# HR_C7000_DM32 register map
Vendor: Dahua Technology (chip); Baofeng (radio product); Series: HR_C7000; File version: 0.1-dm32re-draft
CPU: other r0p0, little endian, no MPU, no FPU, 0 interrupt priority bits
Registers are 32-bit, read-write, reset 0x0 unless marked. A register's access mark holds for its fields unless they carry their own. Offsets are from the block's base; [hi:lo] are bit positions; {n}, {i} and the like mark numbered series; <NAME> marks a mode.

## PIC (part 1 of 2) — Programmable interrupt controller, 64 sources of which Table 30 assigns 38 (DS §4.7, p.166-187; Register Table 5 p.170-172). This is the chip's real interrupt controller, not the CK803S built-in VIC at 0xE000E100: the stock firmware makes no 0xE000xxxx accesses (program-flash sweep and live register reads). SOURCE vs VECTOR: source n is bit n of PIC_MODE/PO/MASK/INT_ST/FFLAG_L (n < 32) or bit n-32 of PIC_MODE_1/PO_1/MASK_1/INT_ST_1/FFLAG_H, and byte n%4 of PIC_PRIOR<4*(n/4)>; the CPU sees it as vector n + PIC_VECTOR.vector0 = n + 32 at reset. Table 30 (p.168-169), source/vector: 0 reserved/32, 1 TIMER_1/33, 2 TIMER_2/34, 3 TIMER_3/35, 4 TIMER_4/36, 5 TIMER_5/37, 6 TIMER_6/38, 7 I2C1/39, 8 I2C0/40, 9 I2C2/41, 10 UART1/42, 11 UART2/43, 12 UART0/44, 13 UART3/45, 14 GPIOB/46, 15 GPIOA/47, 16 SPI0/48, 17 GPIOC/49, 18 PWM/50, 19 RTC/51, 20 SDIO/52, 21 USB/53, 22 SPI1/54, 23 SPI2/55, 24 LCSFC/56, 25 DAC/57, 26 ADC/58, 27 PCM_rd_data_interp/59, 28 PCM_wr_data_interp/60, 29 System_inter/61, 30 Time_slot_inter_tx/62, 31 Time_slot_inter_rx/63, 32 Rf_tx_inter/64, 33 Rf_rx_inter/65, 34 SlaveSPI0/66, 35 SlaveSPI1/67, 36 SlaveSPI2/68, 37 Codec_interp/69; all level-triggered, active high. CORRECTED 2026-10-10: the hand-maintained description this replaced listed CPU vectors as 'source assignments' (TIMER_1=33, TIMER_2-4=34-36, UART3=45, GPIOC=49, PCM_rd/wr_data_interp=59/60, System_inter=61, Time_slot_inter_rx=63, Rf_rx_inter=65, Codec_interp=69, and UART1/2/0=42/43/44, ADC=58, Rf_tx=64). Those are vectors; the sources are 1, 2-4, 13, 17, 27/28, 29, 31, 33, 37, 10/11/12, 26, 32. DRV's VECTOR_* defines (C7000_DRV.h: VECTOR_TIMER1-4=33-36, UART3=45, GPIOC=49, PCM_rd/wr_data_interp=59/60, System_inter=61, Time_slot_inter_rx=63, Rf_rx_inter=65, Codec_interp=69; bsp_vic.h: VECTOR_TIMER0=33, VECTOR_USB=53) are vectors too, passed to CKSetIsrVector, which unmasks bit (vector - 32); they agree with Table 30's vector column at every entry. The earlier note that a live trace's 'Time_slot_inter_tx = source 30' and DRV's 'Time_slot_inter_rx = 63' were an unverified TX/RX pair is resolved: Table 30 has tx at source 30/vector 62 and rx at source 31/vector 63. RTOS TICK: TIMER_1 (timer channel 0) is PIC source 1, CPU vector 33. Confirmed on hardware 2026-10-01 (OpenRTX bring-up on a DM-32UV, boot console log): with source 33 unmasked instead, the timer expired and held its line but nothing was delivered; with source 1 unmasked the ISR fired. The stock firmware registers its tick ISR with vector 33, stored at ISR-table index 33 - 32 = 1 (flash 0x0306cf70/0x0306cf38; dm32uv-qemu board-model notes (DM32-BOARD-MODEL.md), session 7). Register names and offsets also come from DRV bsp_vic.h ('Interrupt Controller definitions', Wang Huibin, 2013-05-13; in the DemoUV008 source tree at ucos3/include/bsp/bsp_vic.h), which agrees with Register Table 5 at every offset. Its CKIntcInit (bsp_vic.c) writes MODE = 0, PO = 0xffffffff, MASK = 0xffffffff, MODE_1 = 0, PO_1 = 0xffffffff, then MASK a second time where MASK_1 was probably meant, then INT_ST/INT_ST_1 = 0xffffffff. FW: 24 access sites in 2 code regions, all to MODE/PO/MASK/INT_ST and their upper-bank siblings; no access to PIC_VECTOR, PIC_COW1/2, PIC_PRIOR*, PIC_SYNC or PIC_FFLAG_* was found by the program-flash sweep, which does not cover IRAM (where the interrupt entry path runs).
Base 0x17000000
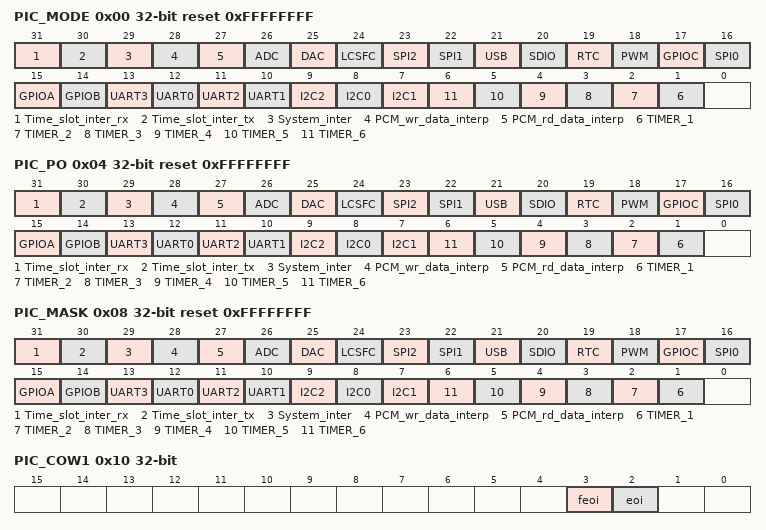
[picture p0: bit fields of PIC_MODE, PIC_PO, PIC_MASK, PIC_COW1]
0x00 PIC_MODE reset 0xFFFFFFFF — Trigger mode select, sources 0-31. DS §4.7.6.1 p.172. FW: 0 reads, 2 writes. Bit n is source 0+n (sources 0-31). The datasheet prints one [31:0] field; it is split here into one bit per source named in Table 30 (p.168-169); bits with no assigned source have no field. Reset is all edge-triggered, while Table 30 requires level/high: DRV's CKIntcInit (bsp_vic.c) writes PIC_MODE = 0 and PIC_PO = 0xffffffff. FW writes this register (count above). Offset previously confirmed by DRV bsp_vic.h. Reset 0xffffffff (DS).
  [31] Time_slot_inter_rx — Trigger mode of source 31 (Time_slot_inter_rx, vector 63). 1: edge; 0: level. Table 30 specifies level-triggered, active high [reset 0x1] [access RW]
  [30] Time_slot_inter_tx — Trigger mode of source 30 (Time_slot_inter_tx, vector 62). 1: edge; 0: level. Table 30 specifies level-triggered, active high [reset 0x1] [access RW]
  [29] System_inter — Trigger mode of source 29 (System_inter, vector 61). 1: edge; 0: level. Table 30 specifies level-triggered, active high [reset 0x1] [access RW]
  [28] PCM_wr_data_interp — Trigger mode of source 28 (PCM_wr_data_interp, vector 60). 1: edge; 0: level. Table 30 specifies level-triggered, active high [reset 0x1] [access RW]
  [27] PCM_rd_data_interp — Trigger mode of source 27 (PCM_rd_data_interp, vector 59). 1: edge; 0: level. Table 30 specifies level-triggered, active high [reset 0x1] [access RW]
  [26] ADC — Trigger mode of source 26 (ADC, vector 58). 1: edge; 0: level. Table 30 specifies level-triggered, active high [reset 0x1] [access RW]
  [25] DAC — Trigger mode of source 25 (DAC, vector 57). 1: edge; 0: level. Table 30 specifies level-triggered, active high [reset 0x1] [access RW]
  [24] LCSFC — Trigger mode of source 24 (LCSFC, vector 56). 1: edge; 0: level. Table 30 specifies level-triggered, active high [reset 0x1] [access RW]
  [23] SPI2 — Trigger mode of source 23 (SPI2, vector 55). 1: edge; 0: level. Table 30 specifies level-triggered, active high [reset 0x1] [access RW]
  [22] SPI1 — Trigger mode of source 22 (SPI1, vector 54). 1: edge; 0: level. Table 30 specifies level-triggered, active high [reset 0x1] [access RW]
  [21] USB — Trigger mode of source 21 (USB, vector 53). 1: edge; 0: level. Table 30 specifies level-triggered, active high [reset 0x1] [access RW]
  [20] SDIO — Trigger mode of source 20 (SDIO, vector 52). 1: edge; 0: level. Table 30 specifies level-triggered, active high [reset 0x1] [access RW]
  [19] RTC — Trigger mode of source 19 (RTC, vector 51). 1: edge; 0: level. Table 30 specifies level-triggered, active high [reset 0x1] [access RW]
  [18] PWM — Trigger mode of source 18 (PWM, vector 50). 1: edge; 0: level. Table 30 specifies level-triggered, active high [reset 0x1] [access RW]
  [17] GPIOC — Trigger mode of source 17 (GPIOC, vector 49). 1: edge; 0: level. Table 30 specifies level-triggered, active high [reset 0x1] [access RW]
  [16] SPI0 — Trigger mode of source 16 (SPI0, vector 48). 1: edge; 0: level. Table 30 specifies level-triggered, active high [reset 0x1] [access RW]
  [15] GPIOA — Trigger mode of source 15 (GPIOA, vector 47). 1: edge; 0: level. Table 30 specifies level-triggered, active high [reset 0x1] [access RW]
  [14] GPIOB — Trigger mode of source 14 (GPIOB, vector 46). 1: edge; 0: level. Table 30 specifies level-triggered, active high [reset 0x1] [access RW]
  [13] UART3 — Trigger mode of source 13 (UART3, vector 45). 1: edge; 0: level. Table 30 specifies level-triggered, active high [reset 0x1] [access RW]
  [12] UART0 — Trigger mode of source 12 (UART0, vector 44). 1: edge; 0: level. Table 30 specifies level-triggered, active high [reset 0x1] [access RW]
  [11] UART2 — Trigger mode of source 11 (UART2, vector 43). 1: edge; 0: level. Table 30 specifies level-triggered, active high [reset 0x1] [access RW]
  [10] UART1 — Trigger mode of source 10 (UART1, vector 42). 1: edge; 0: level. Table 30 specifies level-triggered, active high [reset 0x1] [access RW]
  [9] I2C2 — Trigger mode of source 9 (I2C2, vector 41). 1: edge; 0: level. Table 30 specifies level-triggered, active high [reset 0x1] [access RW]
  [8] I2C0 — Trigger mode of source 8 (I2C0, vector 40). 1: edge; 0: level. Table 30 specifies level-triggered, active high [reset 0x1] [access RW]
  [7] I2C1 — Trigger mode of source 7 (I2C1, vector 39). 1: edge; 0: level. Table 30 specifies level-triggered, active high [reset 0x1] [access RW]
  [n] TIMER_{n} (n=1..6) — Trigger mode of source {n} (TIMER_{n}, vector {n+32}). 1: edge; 0: level. Table 30 specifies level-triggered, active high [reset 0x1] [access RW]
0x04 PIC_PO reset 0xFFFFFFFF — Trigger polarity select, sources 0-31. DS §4.7.6.2 p.172. FW: 0 reads, 2 writes. Bit n is source 0+n (sources 0-31). The datasheet prints one [31:0] field; it is split here into one bit per source named in Table 30 (p.168-169); bits with no assigned source have no field. Offset also in DRV bsp_vic.h. Reset 0xffffffff (DS).
  [31] Time_slot_inter_rx — Trigger polarity of source 31 (Time_slot_inter_rx, vector 63). 1: rising edge / high level; 0: falling edge / low level [reset 0x1] [access RW]
  [30] Time_slot_inter_tx — Trigger polarity of source 30 (Time_slot_inter_tx, vector 62). 1: rising edge / high level; 0: falling edge / low level [reset 0x1] [access RW]
  [29] System_inter — Trigger polarity of source 29 (System_inter, vector 61). 1: rising edge / high level; 0: falling edge / low level [reset 0x1] [access RW]
  [28] PCM_wr_data_interp — Trigger polarity of source 28 (PCM_wr_data_interp, vector 60). 1: rising edge / high level; 0: falling edge / low level [reset 0x1] [access RW]
  [27] PCM_rd_data_interp — Trigger polarity of source 27 (PCM_rd_data_interp, vector 59). 1: rising edge / high level; 0: falling edge / low level [reset 0x1] [access RW]
  [26] ADC — Trigger polarity of source 26 (ADC, vector 58). 1: rising edge / high level; 0: falling edge / low level [reset 0x1] [access RW]
  [25] DAC — Trigger polarity of source 25 (DAC, vector 57). 1: rising edge / high level; 0: falling edge / low level [reset 0x1] [access RW]
  [24] LCSFC — Trigger polarity of source 24 (LCSFC, vector 56). 1: rising edge / high level; 0: falling edge / low level [reset 0x1] [access RW]
  [23] SPI2 — Trigger polarity of source 23 (SPI2, vector 55). 1: rising edge / high level; 0: falling edge / low level [reset 0x1] [access RW]
  [22] SPI1 — Trigger polarity of source 22 (SPI1, vector 54). 1: rising edge / high level; 0: falling edge / low level [reset 0x1] [access RW]
  [21] USB — Trigger polarity of source 21 (USB, vector 53). 1: rising edge / high level; 0: falling edge / low level [reset 0x1] [access RW]
  [20] SDIO — Trigger polarity of source 20 (SDIO, vector 52). 1: rising edge / high level; 0: falling edge / low level [reset 0x1] [access RW]
  [19] RTC — Trigger polarity of source 19 (RTC, vector 51). 1: rising edge / high level; 0: falling edge / low level [reset 0x1] [access RW]
  [18] PWM — Trigger polarity of source 18 (PWM, vector 50). 1: rising edge / high level; 0: falling edge / low level [reset 0x1] [access RW]
  [17] GPIOC — Trigger polarity of source 17 (GPIOC, vector 49). 1: rising edge / high level; 0: falling edge / low level [reset 0x1] [access RW]
  [16] SPI0 — Trigger polarity of source 16 (SPI0, vector 48). 1: rising edge / high level; 0: falling edge / low level [reset 0x1] [access RW]
  [15] GPIOA — Trigger polarity of source 15 (GPIOA, vector 47). 1: rising edge / high level; 0: falling edge / low level [reset 0x1] [access RW]
  [14] GPIOB — Trigger polarity of source 14 (GPIOB, vector 46). 1: rising edge / high level; 0: falling edge / low level [reset 0x1] [access RW]
  [13] UART3 — Trigger polarity of source 13 (UART3, vector 45). 1: rising edge / high level; 0: falling edge / low level [reset 0x1] [access RW]
  [12] UART0 — Trigger polarity of source 12 (UART0, vector 44). 1: rising edge / high level; 0: falling edge / low level [reset 0x1] [access RW]
  [11] UART2 — Trigger polarity of source 11 (UART2, vector 43). 1: rising edge / high level; 0: falling edge / low level [reset 0x1] [access RW]
  [10] UART1 — Trigger polarity of source 10 (UART1, vector 42). 1: rising edge / high level; 0: falling edge / low level [reset 0x1] [access RW]
  [9] I2C2 — Trigger polarity of source 9 (I2C2, vector 41). 1: rising edge / high level; 0: falling edge / low level [reset 0x1] [access RW]
  [8] I2C0 — Trigger polarity of source 8 (I2C0, vector 40). 1: rising edge / high level; 0: falling edge / low level [reset 0x1] [access RW]
  [7] I2C1 — Trigger polarity of source 7 (I2C1, vector 39). 1: rising edge / high level; 0: falling edge / low level [reset 0x1] [access RW]
  [n] TIMER_{n} (n=1..6) — Trigger polarity of source {n} (TIMER_{n}, vector {n+32}). 1: rising edge / high level; 0: falling edge / low level [reset 0x1] [access RW]
0x08 PIC_MASK reset 0xFFFFFFFF — Interrupt mask, sources 0-31. DS §4.7.6.3 p.173. FW: 2 reads, 4 writes. Bit n is source 0+n (sources 0-31). The datasheet prints one [31:0] field; it is split here into one bit per source named in Table 30 (p.168-169); bits with no assigned source have no field. All sources are masked at reset. FW: irq_controller_unmask_and_register_handler @0x0306cf70 and sram_state_word_bit_clear @0x03001c50 take a CPU VECTOR v >= 0x20 and clear bit (v - 0x20) here when v < 0x40, else bit (v - 0x40) of PIC_MASK_1; DRV bsp_vic.c CK_VIC_EnNormalIrq does the same (bit irq_num - 32). So bit n here is source n, as the datasheet says. CORRECTED 2026-10-10: the hand-maintained entry this replaced said PIC_MASK covers sources 32-63 and PIC_MASK_1 sources 64+, reading the firmware's vector argument as a source number. Reset 0xffffffff (DS).
  [31] Time_slot_inter_rx — Mask for source 31 (Time_slot_inter_rx, vector 63). 1: masked; 0: request detection enabled [reset 0x1] [access RW]
  [30] Time_slot_inter_tx — Mask for source 30 (Time_slot_inter_tx, vector 62). 1: masked; 0: request detection enabled [reset 0x1] [access RW]
  [29] System_inter — Mask for source 29 (System_inter, vector 61). 1: masked; 0: request detection enabled [reset 0x1] [access RW]
  [28] PCM_wr_data_interp — Mask for source 28 (PCM_wr_data_interp, vector 60). 1: masked; 0: request detection enabled [reset 0x1] [access RW]
  [27] PCM_rd_data_interp — Mask for source 27 (PCM_rd_data_interp, vector 59). 1: masked; 0: request detection enabled [reset 0x1] [access RW]
  [26] ADC — Mask for source 26 (ADC, vector 58). 1: masked; 0: request detection enabled [reset 0x1] [access RW]
  [25] DAC — Mask for source 25 (DAC, vector 57). 1: masked; 0: request detection enabled [reset 0x1] [access RW]
  [24] LCSFC — Mask for source 24 (LCSFC, vector 56). 1: masked; 0: request detection enabled [reset 0x1] [access RW]
  [23] SPI2 — Mask for source 23 (SPI2, vector 55). 1: masked; 0: request detection enabled [reset 0x1] [access RW]
  [22] SPI1 — Mask for source 22 (SPI1, vector 54). 1: masked; 0: request detection enabled [reset 0x1] [access RW]
  [21] USB — Mask for source 21 (USB, vector 53). 1: masked; 0: request detection enabled [reset 0x1] [access RW]
  [20] SDIO — Mask for source 20 (SDIO, vector 52). 1: masked; 0: request detection enabled [reset 0x1] [access RW]
  [19] RTC — Mask for source 19 (RTC, vector 51). 1: masked; 0: request detection enabled [reset 0x1] [access RW]
  [18] PWM — Mask for source 18 (PWM, vector 50). 1: masked; 0: request detection enabled [reset 0x1] [access RW]
  [17] GPIOC — Mask for source 17 (GPIOC, vector 49). 1: masked; 0: request detection enabled [reset 0x1] [access RW]
  [16] SPI0 — Mask for source 16 (SPI0, vector 48). 1: masked; 0: request detection enabled [reset 0x1] [access RW]
  [15] GPIOA — Mask for source 15 (GPIOA, vector 47). 1: masked; 0: request detection enabled [reset 0x1] [access RW]
  [14] GPIOB — Mask for source 14 (GPIOB, vector 46). 1: masked; 0: request detection enabled [reset 0x1] [access RW]
  [13] UART3 — Mask for source 13 (UART3, vector 45). 1: masked; 0: request detection enabled [reset 0x1] [access RW]
  [12] UART0 — Mask for source 12 (UART0, vector 44). 1: masked; 0: request detection enabled [reset 0x1] [access RW]
  [11] UART2 — Mask for source 11 (UART2, vector 43). 1: masked; 0: request detection enabled [reset 0x1] [access RW]
  [10] UART1 — Mask for source 10 (UART1, vector 42). 1: masked; 0: request detection enabled [reset 0x1] [access RW]
  [9] I2C2 — Mask for source 9 (I2C2, vector 41). 1: masked; 0: request detection enabled [reset 0x1] [access RW]
  [8] I2C0 — Mask for source 8 (I2C0, vector 40). 1: masked; 0: request detection enabled [reset 0x1] [access RW]
  [7] I2C1 — Mask for source 7 (I2C1, vector 39). 1: masked; 0: request detection enabled [reset 0x1] [access RW]
  [n] TIMER_{n} (n=1..6) — Mask for source {n} (TIMER_{n}, vector {n+32}). 1: masked; 0: request detection enabled [reset 0x1] [access RW]
0x0C PIC_VECTOR reset 0x20 — Interrupt vector base address. DS §4.7.6.4 p.174. Source x is delivered to the CPU as vector x + vector0; with the reset vector0 = 32 this gives Table 30's 'default interrupt vector' column (source + 32). The stock firmware's dispatcher indexes its ISR table by (vector - 32) (IRAM 0x1064a; dm32uv-qemu board-model notes (DM32-BOARD-MODEL.md), session 7). Offset first identified from a live register read of a running radio, and also in DRV bsp_vic.h. Reset 0x20 (DS).
  [6:0] vector0 — Vector number for IRQ0, range 32-112. Source x is delivered as vector x + vector0 [reset 0x20] [access RW]
0x10 PIC_COW1 wo — End of interruption. DS §4.7.6.5 p.174. The hand-maintained entry this replaced guessed a 'clear-on-write ack'; the datasheet defines it as the end-of-interrupt register (eoi for normal, feoi for fast interrupts). Offset also in DRV bsp_vic.h. FW: no write found by the program-flash sweep, which does not cover the IRAM interrupt entry path. Reset 0x0 (DS).
  [3] feoi — When the CPU finishes processing the fast interrupt, it writes 1 to this bit . After obtaining FEOI , the interrupt controller clears the FISR register and pulls the FINT (active low) request line high. 1 ： CPU interrupt service ends; 0 ： CPU Still processing outage service. [reset 0x0] [access WO]
  [2] eoi — When the CPU finishes processing the interrupt, it writes 1 to this bit . After receiving the eoi signal, the interrupt controller will clear the ISR register and pull the INT (active low) request line high. 1 ： CPU interrupt service ends; 0 ： CPU Still processing outage service. [reset 0x0] [access WO]
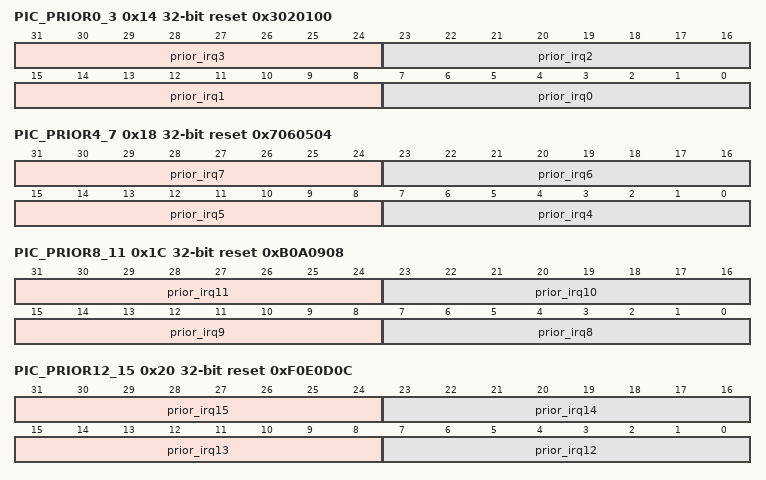
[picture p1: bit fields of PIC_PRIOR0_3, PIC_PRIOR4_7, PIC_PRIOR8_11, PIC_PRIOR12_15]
0x14 PIC_PRIOR0_3 reset 0x3020100 — Priority counter initial values, sources 0-3. DS §4.7.6.6 p.174. Sources 0-3 are unassigned, TIMER_1, TIMER_2, TIMER_3; one byte each, source 0 in [7:0]. Offset also in DRV bsp_vic.h as PIC_PRIOR0_3. FW: no access found by the program-flash sweep (which does not cover IRAM code). Reset 0x3020100 (DS).
  [31:24] prior_irq3 — Priority counter initial value for source 3 (TIMER_3, vector 35); smaller is higher priority. Used only when PIC_COW2.priority = 1. Reset value n gives the same order as the fixed default IRQ0 > IRQ1 > ... > IRQ63 [reset 0x3] [access RW]
  [23:16] prior_irq2 — Priority counter initial value for source 2 (TIMER_2, vector 34); smaller is higher priority. Used only when PIC_COW2.priority = 1. Reset value n gives the same order as the fixed default IRQ0 > IRQ1 > ... > IRQ63 [reset 0x2] [access RW]
  [15:8] prior_irq1 — Priority counter initial value for source 1 (TIMER_1, vector 33); smaller is higher priority. Used only when PIC_COW2.priority = 1. Reset value n gives the same order as the fixed default IRQ0 > IRQ1 > ... > IRQ63 [reset 0x1] [access RW]
  [7:0] prior_irq0 — Priority counter initial value for source 0 (printed 'reserve' in Table 30); smaller is higher priority. Used only when PIC_COW2.priority = 1. Reset value n gives the same order as the fixed default IRQ0 > IRQ1 > ... > IRQ63 [reset 0x0] [access RW]
0x18 PIC_PRIOR4_7 reset 0x7060504 — Priority counter initial values, sources 4-7. DS §4.7.6.7 p.176. Sources 4-7 are TIMER_4, TIMER_5, TIMER_6, I2C1; one byte each, source 4 in [7:0]. Offset also in DRV bsp_vic.h as PIC_PRIOR4_7. FW: no access found by the program-flash sweep (which does not cover IRAM code). Reset 0x7060504 (DS).
  [31:24] prior_irq7 — Priority counter initial value for source 7 (I2C1, vector 39); smaller is higher priority. Used only when PIC_COW2.priority = 1. Reset value n gives the same order as the fixed default IRQ0 > IRQ1 > ... > IRQ63 [reset 0x7] [access RW]
  [23:16] prior_irq6 — Priority counter initial value for source 6 (TIMER_6, vector 38); smaller is higher priority. Used only when PIC_COW2.priority = 1. Reset value n gives the same order as the fixed default IRQ0 > IRQ1 > ... > IRQ63 [reset 0x6] [access RW]
  [15:8] prior_irq5 — Priority counter initial value for source 5 (TIMER_5, vector 37); smaller is higher priority. Used only when PIC_COW2.priority = 1. Reset value n gives the same order as the fixed default IRQ0 > IRQ1 > ... > IRQ63 [reset 0x5] [access RW]
  [7:0] prior_irq4 — Priority counter initial value for source 4 (TIMER_4, vector 36); smaller is higher priority. Used only when PIC_COW2.priority = 1. Reset value n gives the same order as the fixed default IRQ0 > IRQ1 > ... > IRQ63 [reset 0x4] [access RW]
0x1C PIC_PRIOR8_11 reset 0xB0A0908 — Priority counter initial values, sources 8-11. DS §4.7.6.8 p.176. Sources 8-11 are I2C0, I2C2, UART1, UART2; one byte each, source 8 in [7:0]. Offset also in DRV bsp_vic.h as PIC_PRIOR8_11. FW: no access found by the program-flash sweep (which does not cover IRAM code). Reset 0xb0a0908 (DS).
  [31:24] prior_irq11 — Priority counter initial value for source 11 (UART2, vector 43); smaller is higher priority. Used only when PIC_COW2.priority = 1. Reset value n gives the same order as the fixed default IRQ0 > IRQ1 > ... > IRQ63 [reset 0xb] [access RW]
  [23:16] prior_irq10 — Priority counter initial value for source 10 (UART1, vector 42); smaller is higher priority. Used only when PIC_COW2.priority = 1. Reset value n gives the same order as the fixed default IRQ0 > IRQ1 > ... > IRQ63 [reset 0xa] [access RW]
  [15:8] prior_irq9 — Priority counter initial value for source 9 (I2C2, vector 41); smaller is higher priority. Used only when PIC_COW2.priority = 1. Reset value n gives the same order as the fixed default IRQ0 > IRQ1 > ... > IRQ63 [reset 0x9] [access RW]
  [7:0] prior_irq8 — Priority counter initial value for source 8 (I2C0, vector 40); smaller is higher priority. Used only when PIC_COW2.priority = 1. Reset value n gives the same order as the fixed default IRQ0 > IRQ1 > ... > IRQ63 [reset 0x8] [access RW]
0x20 PIC_PRIOR12_15 reset 0xF0E0D0C — Priority counter initial values, sources 12-15. DS §4.7.6.9 p.176. Sources 12-15 are UART0, UART3, GPIOB, GPIOA; one byte each, source 12 in [7:0]. Offset also in DRV bsp_vic.h as PIC_PRIOR12_15. FW: no access found by the program-flash sweep (which does not cover IRAM code). Reset 0xf0e0d0c (DS).
  [31:24] prior_irq15 — Priority counter initial value for source 15 (GPIOA, vector 47); smaller is higher priority. Used only when PIC_COW2.priority = 1. Reset value n gives the same order as the fixed default IRQ0 > IRQ1 > ... > IRQ63 [reset 0xf] [access RW]
  [23:16] prior_irq14 — Priority counter initial value for source 14 (GPIOB, vector 46); smaller is higher priority. Used only when PIC_COW2.priority = 1. Reset value n gives the same order as the fixed default IRQ0 > IRQ1 > ... > IRQ63 [reset 0xe] [access RW]
  [15:8] prior_irq13 — Priority counter initial value for source 13 (UART3, vector 45); smaller is higher priority. Used only when PIC_COW2.priority = 1. Reset value n gives the same order as the fixed default IRQ0 > IRQ1 > ... > IRQ63 [reset 0xd] [access RW]
  [7:0] prior_irq12 — Priority counter initial value for source 12 (UART0, vector 44); smaller is higher priority. Used only when PIC_COW2.priority = 1. Reset value n gives the same order as the fixed default IRQ0 > IRQ1 > ... > IRQ63 [reset 0xc] [access RW]
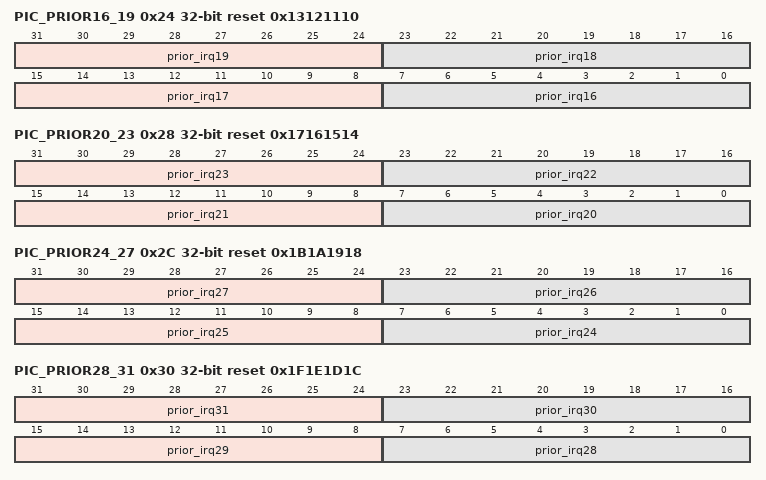
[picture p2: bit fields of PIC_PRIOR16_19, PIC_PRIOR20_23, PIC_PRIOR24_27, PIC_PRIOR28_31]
0x24 PIC_PRIOR16_19 reset 0x13121110 — Priority counter initial values, sources 16-19. DS §4.7.6.10 p.176. Sources 16-19 are SPI0, GPIOC, PWM, RTC; one byte each, source 16 in [7:0]. Offset also in DRV bsp_vic.h as PIC_PRIOR16_19. FW: no access found by the program-flash sweep (which does not cover IRAM code). Reset 0x13121110 (DS).
  [31:24] prior_irq19 — Priority counter initial value for source 19 (RTC, vector 51); smaller is higher priority. Used only when PIC_COW2.priority = 1. Reset value n gives the same order as the fixed default IRQ0 > IRQ1 > ... > IRQ63 [reset 0x13] [access RW]
  [23:16] prior_irq18 — Priority counter initial value for source 18 (PWM, vector 50); smaller is higher priority. Used only when PIC_COW2.priority = 1. Reset value n gives the same order as the fixed default IRQ0 > IRQ1 > ... > IRQ63 [reset 0x12] [access RW]
  [15:8] prior_irq17 — Priority counter initial value for source 17 (GPIOC, vector 49); smaller is higher priority. Used only when PIC_COW2.priority = 1. Reset value n gives the same order as the fixed default IRQ0 > IRQ1 > ... > IRQ63 [reset 0x11] [access RW]
  [7:0] prior_irq16 — Priority counter initial value for source 16 (SPI0, vector 48); smaller is higher priority. Used only when PIC_COW2.priority = 1. Reset value n gives the same order as the fixed default IRQ0 > IRQ1 > ... > IRQ63 [reset 0x10] [access RW]
0x28 PIC_PRIOR20_23 reset 0x17161514 — Priority counter initial values, sources 20-23. DS §4.7.6.11 p.177. Sources 20-23 are SDIO, USB, SPI1, SPI2; one byte each, source 20 in [7:0]. Offset also in DRV bsp_vic.h as PIC_PRIOR20_23. FW: no access found by the program-flash sweep (which does not cover IRAM code). Reset 0x17161514 (DS).
  [31:24] prior_irq23 — Priority counter initial value for source 23 (SPI2, vector 55); smaller is higher priority. Used only when PIC_COW2.priority = 1. Reset value n gives the same order as the fixed default IRQ0 > IRQ1 > ... > IRQ63 [reset 0x17] [access RW]
  [23:16] prior_irq22 — Priority counter initial value for source 22 (SPI1, vector 54); smaller is higher priority. Used only when PIC_COW2.priority = 1. Reset value n gives the same order as the fixed default IRQ0 > IRQ1 > ... > IRQ63 [reset 0x16] [access RW]
  [15:8] prior_irq21 — Priority counter initial value for source 21 (USB, vector 53); smaller is higher priority. Used only when PIC_COW2.priority = 1. Reset value n gives the same order as the fixed default IRQ0 > IRQ1 > ... > IRQ63 [reset 0x15] [access RW]
  [7:0] prior_irq20 — Priority counter initial value for source 20 (SDIO, vector 52); smaller is higher priority. Used only when PIC_COW2.priority = 1. Reset value n gives the same order as the fixed default IRQ0 > IRQ1 > ... > IRQ63 [reset 0x14] [access RW]
0x2C PIC_PRIOR24_27 reset 0x1B1A1918 — Priority counter initial values, sources 24-27. DS §4.7.6.12 p.178. Sources 24-27 are LCSFC, DAC, ADC, PCM_rd_data_interp; one byte each, source 24 in [7:0]. Offset also in DRV bsp_vic.h as PIC_PRIOR24_27. FW: no access found by the program-flash sweep (which does not cover IRAM code). Reset 0x1b1a1918 (DS).
  [31:24] prior_irq27 — Priority counter initial value for source 27 (PCM_rd_data_interp, vector 59); smaller is higher priority. Used only when PIC_COW2.priority = 1. Reset value n gives the same order as the fixed default IRQ0 > IRQ1 > ... > IRQ63 [reset 0x1b] [access RW]
  [23:16] prior_irq26 — Priority counter initial value for source 26 (ADC, vector 58); smaller is higher priority. Used only when PIC_COW2.priority = 1. Reset value n gives the same order as the fixed default IRQ0 > IRQ1 > ... > IRQ63 [reset 0x1a] [access RW]
  [15:8] prior_irq25 — Priority counter initial value for source 25 (DAC, vector 57); smaller is higher priority. Used only when PIC_COW2.priority = 1. Reset value n gives the same order as the fixed default IRQ0 > IRQ1 > ... > IRQ63 [reset 0x19] [access RW]
  [7:0] prior_irq24 — Priority counter initial value for source 24 (LCSFC, vector 56); smaller is higher priority. Used only when PIC_COW2.priority = 1. Reset value n gives the same order as the fixed default IRQ0 > IRQ1 > ... > IRQ63 [reset 0x18] [access RW]
0x30 PIC_PRIOR28_31 reset 0x1F1E1D1C — Priority counter initial values, sources 28-31. DS §4.7.6.13 p.178. Sources 28-31 are PCM_wr_data_interp, System_inter, Time_slot_inter_tx, Time_slot_inter_rx; one byte each, source 28 in [7:0]. Offset also in DRV bsp_vic.h as PIC_PRIOR28_31. FW: no access found by the program-flash sweep (which does not cover IRAM code). Reset 0x1f1e1d1c (DS).
  [31:24] prior_irq31 — Priority counter initial value for source 31 (Time_slot_inter_rx, vector 63); smaller is higher priority. Used only when PIC_COW2.priority = 1. Reset value n gives the same order as the fixed default IRQ0 > IRQ1 > ... > IRQ63 [reset 0x1f] [access RW]
  [23:16] prior_irq30 — Priority counter initial value for source 30 (Time_slot_inter_tx, vector 62); smaller is higher priority. Used only when PIC_COW2.priority = 1. Reset value n gives the same order as the fixed default IRQ0 > IRQ1 > ... > IRQ63 [reset 0x1e] [access RW]
  [15:8] prior_irq29 — Priority counter initial value for source 29 (System_inter, vector 61); smaller is higher priority. Used only when PIC_COW2.priority = 1. Reset value n gives the same order as the fixed default IRQ0 > IRQ1 > ... > IRQ63 [reset 0x1d] [access RW]
  [7:0] prior_irq28 — Priority counter initial value for source 28 (PCM_wr_data_interp, vector 60); smaller is higher priority. Used only when PIC_COW2.priority = 1. Reset value n gives the same order as the fixed default IRQ0 > IRQ1 > ... > IRQ63 [reset 0x1c] [access RW]
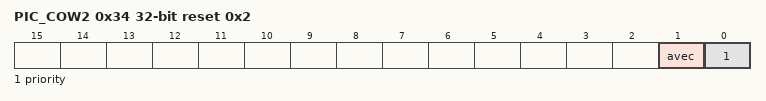
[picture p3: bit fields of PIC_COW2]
0x34 PIC_COW2 reset 0x2 — Control registers. DS §4.7.6.14 p.178. Not an upper-bank sibling of PIC_COW1, as the hand-maintained entry this replaced guessed: it is the vector-mode and priority-mode control. Offset also in DRV bsp_vic.h. Reset 0x2 (DS).
  [1] avec — 1: the CPU uses the vector number sent by the interrupt controller; 0: the CPU uses the automatic vector number 0x28 or 0x2c [reset 0x1] [access RW]
  [0] priority — 1: use the per-source priority counters in PIC_PRIOR* (smaller initial value = higher priority); 0: default fixed priority IRQ0 > IRQ1 > ... > IRQ63 [reset 0x0] [access RW]
0x38 PIC_SYNC — Asynchronous Process Control Register. DS §4.7.6.15 p.179. Offset also in DRV bsp_vic.h. Reset 0x0 (DS).
  [7:0] min_interval — Minimum interval used by the asynchronous (clock-domain-crossing) request processing: after the first pulse the level is held for a time that depends on the two clock domains' frequency difference, and this keeps two close pulses from both being lost [reset 0x0] [access RW]
